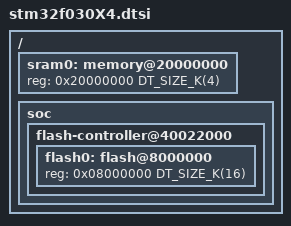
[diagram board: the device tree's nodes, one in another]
/*
 * Copyright (c) 2019 Antony Pavlov <antonynpavlov@gmail.com>
 *
 * SPDX-License-Identifier: Apache-2.0
 */

#include <st/f0/stm32f030.dtsi>

/ {
	sram0: memory@20000000 {
		reg = <0x20000000 DT_SIZE_K(4)>;
	};

	soc {
		flash-controller@40022000 {
			flash0: flash@8000000 {
				reg = <0x08000000 DT_SIZE_K(16)>;
				ranges = <0x0 0x8000000 DT_SIZE_K(16)>;
				#address-cells = <1>;
				#size-cells = <1>;
			};
		};
	};
};
